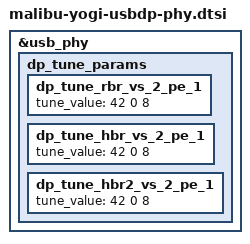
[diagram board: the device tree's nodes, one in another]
// SPDX-License-Identifier: GPL-2.0-only
/*
 * Yogi USBDP PHY device tree
 *
 * Copyright 2025 Google LLC
 *
 */

&usb_phy {
	dp_tune_params {
		/* RBR */
		dp_tune_rbr_vs_2_pe_1 {
			tune_value = <42 0 8>;
		};

		/* HBR */
		dp_tune_hbr_vs_2_pe_1 {
			tune_value = <42 0 8>;
		};

		/* HBR2 */
		dp_tune_hbr2_vs_2_pe_1 {
			tune_value = <42 0 8>;
		};
	};
};
